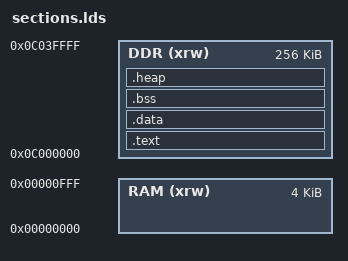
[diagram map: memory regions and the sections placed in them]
/*
This is free and unencumbered software released into the public domain.

Anyone is free to copy, modify, publish, use, compile, sell, or
distribute this software, either in source code form or as a compiled
binary, for any purpose, commercial or non-commercial, and by any
means.
*/

MEMORY
{
    RAM (xrw) : ORIGIN = 0x00000000, LENGTH = 0x1000
    DDR (xrw) : ORIGIN = 0x0c000000, LENGTH = 0x40000
}
SECTIONS {
    .text :
    {
        . = ALIGN(4);
        *(.text)
        *(.text*)
        *(.rodata)
        *(.rodata*)
        *(.srodata)
        *(.srodata*)
        . = ALIGN(4);
        _etext = .;
        _sidata = _etext;
    } >DDR
    .data :
    {
        . = ALIGN(4);
        _sdata = .;
        _ram_start = .;
        . = ALIGN(4);
        *(.data)
        *(.data*)
        *(.sdata)
        *(.sdata*)
        . = ALIGN(4);
        _edata = .;
    } >DDR
    .bss :
    {
        . = ALIGN(4);
        _sbss = .;
        *(.bss)
        *(.bss*)
        *(.sbss)
        *(.sbss*)
        *(COMMON)
        . = ALIGN(4);
        _ebss = .;
    } >DDR
    .heap :
    {
        . = ALIGN(4);
        _heap_start = .;
    } >DDR
}
